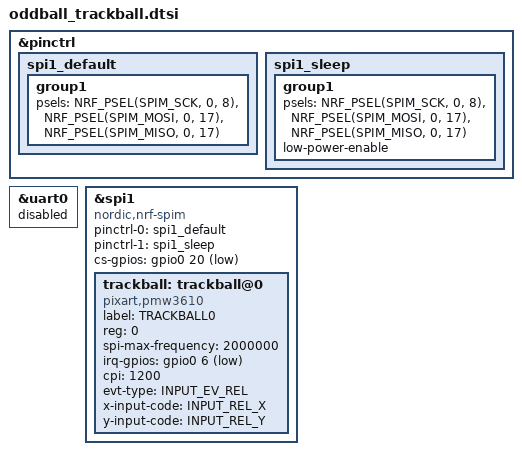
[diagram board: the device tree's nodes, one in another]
/*
 * Copyright (c) 2020 Pete Johanson
 *
 * SPDX-License-Identifier: MIT
 */

#define INPUT_EV_KEY 0x01               /**< Key event */
#define INPUT_EV_REL 0x02               /**< Relative coordinate event */
#define INPUT_EV_ABS 0x03               /**< Absolute coordinate event */
#define INPUT_EV_MSC 0x04               /**< Miscellaneous event */
#define INPUT_EV_VENDOR_START 0xf0      /**< Vendor specific event start */
#define INPUT_EV_VENDOR_STOP 0xff       /**< Vendor specific event stop */

#define INPUT_REL_X 0x00                /**< Relative X coordinate */
#define INPUT_REL_Y 0x01                /**< Relative Y coordinate */
#define INPUT_REL_WHEEL 0x08            /**< Relative wheel coordinate */
#define INPUT_REL_HWHEEL 0x06           /**< Relative horizontal wheel coordinate */
#define INPUT_REL_MISC 0x09             /**< Relative misc coordinate */

&pinctrl {
    spi1_default: spi1_default {
        group1 {
            psels = <NRF_PSEL(SPIM_SCK, 0, 8)>,
                <NRF_PSEL(SPIM_MOSI, 0, 17)>,
                <NRF_PSEL(SPIM_MISO, 0, 17)>;
        };
    };

    spi1_sleep: spi1_sleep {
        group1 {
            psels = <NRF_PSEL(SPIM_SCK, 0, 8)>,
                <NRF_PSEL(SPIM_MOSI, 0, 17)>,
                <NRF_PSEL(SPIM_MISO, 0, 17)>;
            low-power-enable;
        };
    };
};

// release gpio1 12 & 13 from xiao_ble-pinctrl.dtsi
// for &trackball { irq-gpios }
&uart0 {
	status = "disabled";
};

&spi1 {
	compatible = "nordic,nrf-spim";
    status = "okay";
	pinctrl-0 = <&spi1_default>;
	pinctrl-1 = <&spi1_sleep>;
	pinctrl-names = "default", "sleep";
	cs-gpios = <&gpio0 20 GPIO_ACTIVE_LOW>;
	trackball: trackball@0 {
		compatible = "pixart,pmw3610";
		status = "okay";
		label = "TRACKBALL0";
		reg = <0>;
		spi-max-frequency = <2000000>;
        irq-gpios = <&gpio0 6 (GPIO_ACTIVE_LOW | GPIO_PULL_UP)>;
	    cpi = <1200>;
	    evt-type = <INPUT_EV_REL>;
	    x-input-code = <INPUT_REL_X>;
	    y-input-code = <INPUT_REL_Y>;
	};
};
